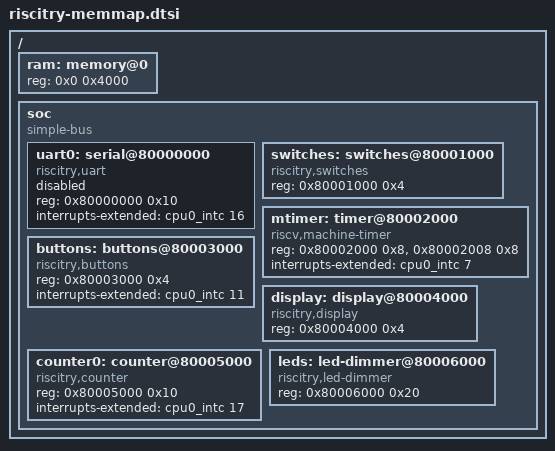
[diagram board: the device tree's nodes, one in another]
/* GENERATED by tools/gen_dts.py from tools/memmap.py. Do not edit; rerun the script.
 * Every address and size here is the hardware's (source/computer/computer.luc decodes the same map).
 * Included by riscitry.dtsi; the cpu0_intc label is defined there. */

/ {
	ram: memory@0 {
		device_type = "memory";
		reg = <0x0 0x4000>;
	};

	soc {
		#address-cells = <1>;
		#size-cells = <1>;
		compatible = "simple-bus";
		ranges;

		/* TXDATA +0, STATUS +4, RXDATA +8 (the read pops). RX interrupt = platform line 0. */
		uart0: serial@80000000 {
			compatible = "riscitry,uart";
			reg = <0x80000000 0x10>;
			interrupts-extended = <&cpu0_intc 16>;
			status = "disabled";
		};

		/* Read-only: the middle DIP bank, bits 7:0 (the boot menu's choice). */
		switches: switches@80001000 {
			compatible = "riscitry,switches";
			reg = <0x80001000 0x4>;
		};

		/* mtime +0, mtimecmp +8, both 64-bit, word access only. Ticks are 1 us on the board.
		 * (A read-only timebase word at +0x10 holds the clocks per tick.) */
		mtimer: timer@80002000 {
			compatible = "riscv,machine-timer";
			reg = <0x80002000 0x8>, <0x80002008 0x8>;
			reg-names = "mtime", "mtimecmp";
			interrupts-extended = <&cpu0_intc 7>;
		};

		/* Direction buttons: pending [3:0], overrun [7:4], levels [11:8]; the external interrupt. */
		buttons: buttons@80003000 {
			compatible = "riscitry,buttons";
			reg = <0x80003000 0x4>;
			interrupts-extended = <&cpu0_intc 11>;
		};

		/* Four characters, byte k = digit k from the left. */
		display: display@80004000 {
			compatible = "riscitry,display";
			reg = <0x80004000 0x4>;
		};

		/* CTRL +0, TOP +4, COUNT +8, STATUS +12. Overflow interrupt = platform line 1. */
		counter0: counter@80005000 {
			compatible = "riscitry,counter";
			reg = <0x80005000 0x10>;
			interrupts-extended = <&cpu0_intc 17>;
		};

		/* 24 duty bytes at +0, CTRL at +0x18. */
		leds: led-dimmer@80006000 {
			compatible = "riscitry,led-dimmer";
			reg = <0x80006000 0x20>;
		};
	};
};
